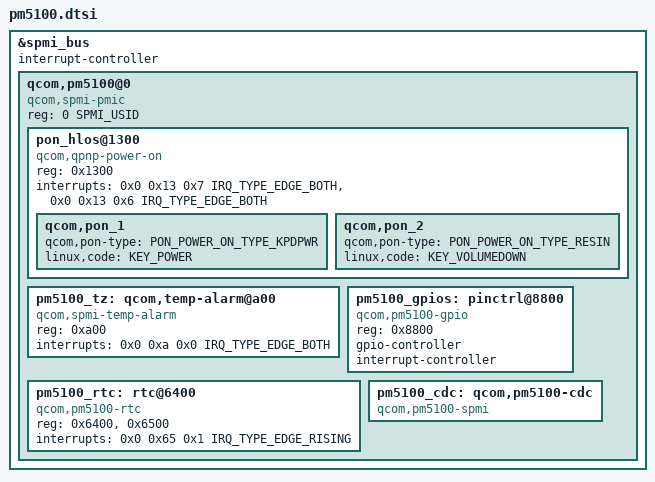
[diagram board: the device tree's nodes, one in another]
#include <dt-bindings/input/input.h>
#include <dt-bindings/input/qcom,qpnp-power-on.h>
#include <dt-bindings/spmi/spmi.h>

&spmi_bus {
	#address-cells = <2>;
	#size-cells = <0>;
	interrupt-controller;
	#interrupt-cells = <4>;

	qcom,pm5100@0 {
		compatible = "qcom,spmi-pmic";
		reg = <0 SPMI_USID>;
		#address-cells = <1>;
		#size-cells = <0>;

		pon_hlos@1300 {
			compatible = "qcom,qpnp-power-on";
			reg = <0x1300>;
			interrupts = <0x0 0x13 0x7 IRQ_TYPE_EDGE_BOTH>,
				     <0x0 0x13 0x6 IRQ_TYPE_EDGE_BOTH>;
			interrupt-names = "kpdpwr", "resin";

			qcom,pon_1 {
				qcom,pon-type = <PON_POWER_ON_TYPE_KPDPWR>;
				linux,code = <KEY_POWER>;
			};

			qcom,pon_2 {
				qcom,pon-type = <PON_POWER_ON_TYPE_RESIN>;
				linux,code = <KEY_VOLUMEDOWN>;
			};
		};

		pm5100_tz: qcom,temp-alarm@a00 {
			compatible = "qcom,spmi-temp-alarm";
			reg = <0xa00>;
			interrupts = <0x0 0xa 0x0 IRQ_TYPE_EDGE_BOTH>;
			#thermal-sensor-cells = <0>;
		};

		pm5100_gpios: pinctrl@8800 {
			compatible = "qcom,pm5100-gpio";
			reg = <0x8800>;
			gpio-controller;
			#gpio-cells = <2>;
			interrupt-controller;
			#interrupt-cells = <2>;
		};

		pm5100_rtc: rtc@6400 {
			compatible = "qcom,pm5100-rtc";
			reg = <0x6400>, <0x6500>;
			reg-names = "rtc", "alarm";
			interrupts = <0x0 0x65 0x1 IRQ_TYPE_EDGE_RISING>;
		};

		pm5100_cdc: qcom,pm5100-cdc {
			compatible = "qcom,pm5100-spmi";
		};
	};
};
